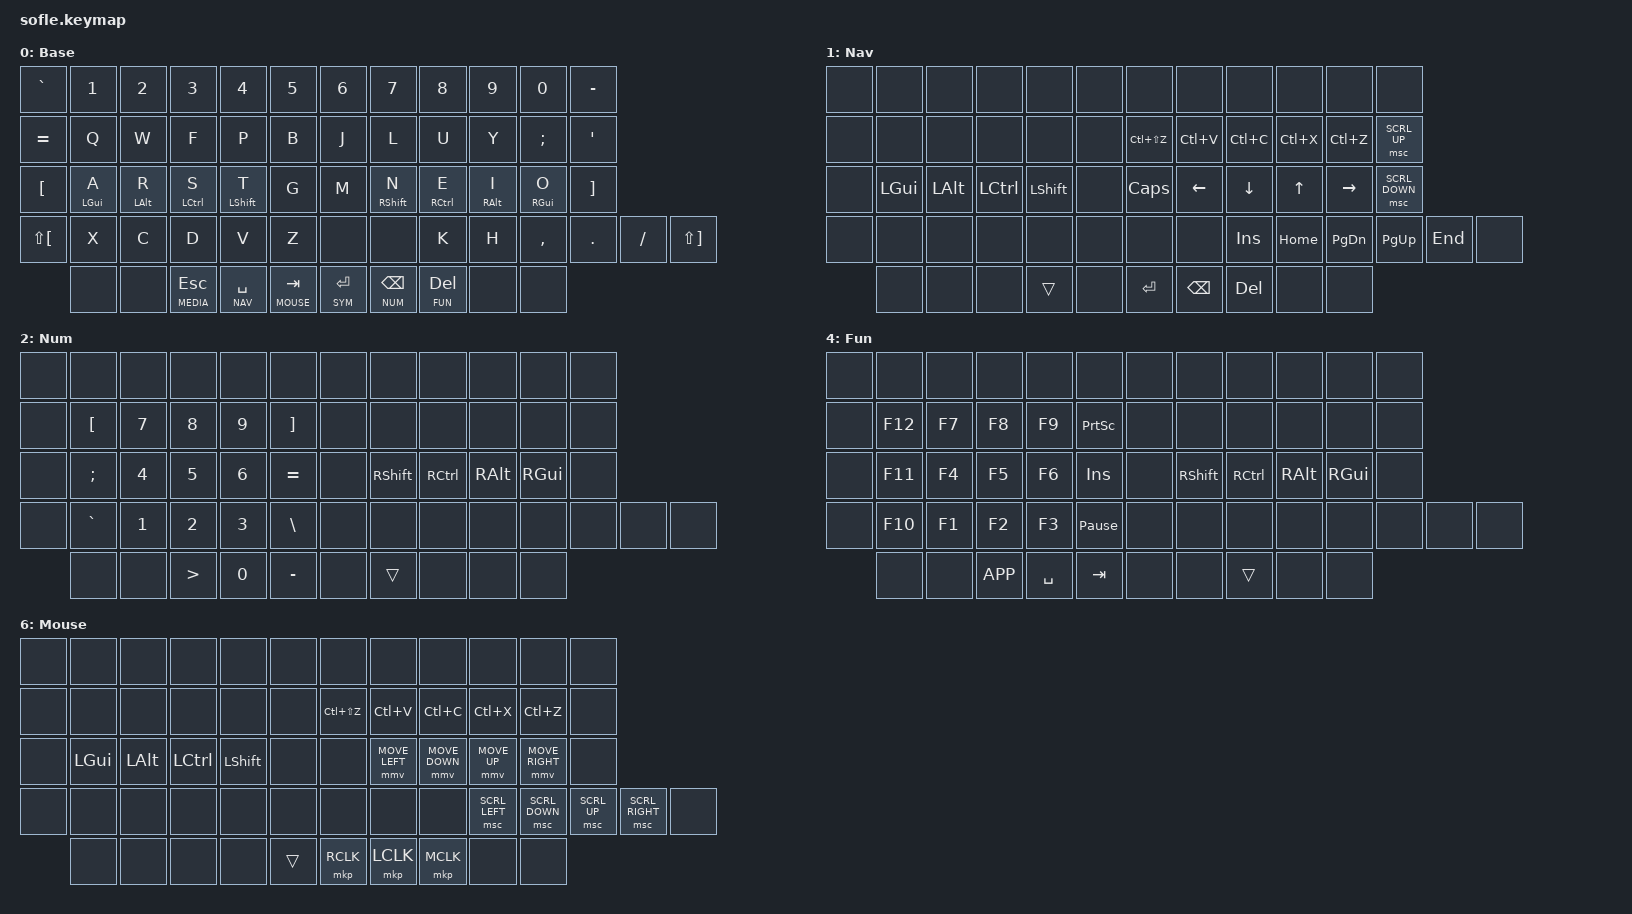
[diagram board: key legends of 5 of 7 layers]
/*
 * SPDX-License-Identifier: MIT
 */

#include <behaviors.dtsi>
#include <dt-bindings/zmk/keys.h>
#include <dt-bindings/zmk/rgb.h>
#include <dt-bindings/zmk/ext_power.h>
#include <dt-bindings/zmk/bt.h>
#include <dt-bindings/zmk/pointing.h>
#include <dt-bindings/zmk/outputs.h>

/* Layers */
#define BASE      0
#define NAV       1
#define NUM       2
#define SYM       3
#define FUN       4
#define MEDIA     5
#define MOUSE     6

/* Miryoku-ish tuning */
#define TAPPING_TERM 280
#define QUICK_TAP    175
#define U_UND &kp LC(Z)
#define U_RDO &kp LC(LS(Z))
#define U_CPY &kp LC(C)
#define U_PST &kp LC(V)
#define U_CUT &kp LC(X)

/ {
  behaviors {
    hm: homerow_mods {
      compatible = "zmk,behavior-hold-tap";
      label = "HM";
      #binding-cells = <2>;
      tapping-term-ms = <TAPPING_TERM>;
      quick-tap-ms = <QUICK_TAP>;
      flavor = "balanced";
      bindings = <&kp>, <&kp>;
    };

    lt: layer_tap {
      compatible = "zmk,behavior-hold-tap";
      label = "LT";
      #binding-cells = <2>;
      tapping-term-ms = <TAPPING_TERM>;
      quick-tap-ms = <QUICK_TAP>;
      flavor = "balanced";
      bindings = <&mo>, <&kp>;
    };

    enc_scroll: enc_scroll {
      compatible = "zmk,behavior-sensor-rotate";
      label = "ENC_SCROLL";
      #sensor-binding-cells = <0>;
      bindings = <&msc SCRL_UP>, <&msc SCRL_DOWN>;
    };

    rgb_toggle_morph: rgb_toggle_morph { 
      compatible = "zmk,behavior-mod-morph";
      #binding-cells = <0>;
      mods = <(MOD_LSFT|MOD_RSFT)>;
      bindings = <&rgb_ug RGB_TOG>, <&rgb_ug RGB_OFF>;
    };

    rgb_eff_morph: rgb_val_morph {
      compatible = "zmk,behavior-mod-morph";
      #binding-cells = <0>;
      mods = <(MOD_LSFT|MOD_RSFT)>;
      bindings = <&rgb_ug RGB_EFF>, <&rgb_ug RGB_EFR>;
    };

    rgb_hue_morph: rgb_hue_morph {
      compatible = "zmk,behavior-mod-morph";
      #binding-cells = <0>;
      mods = <(MOD_LSFT|MOD_RSFT)>;
      bindings = <&rgb_ug RGB_HUI>, <&rgb_ug RGB_HUD>;
    };

    rgb_sat_morph: rgb_sat_morph {
      compatible = "zmk,behavior-mod-morph";
      #binding-cells = <0>;
      mods = <(MOD_LSFT|MOD_RSFT)>;
      bindings = <&rgb_ug RGB_SAI>, <&rgb_ug RGB_SAD>;
    };

    vol_morph: vol_morph {
      compatible = "zmk,behavior-mod-morph";
      #binding-cells = <0>;
      mods = <(MOD_LSFT|MOD_RSFT)>;
      bindings = <&rgb_ug RGB_BRI>, <&rgb_ug RGB_BRD>;
    };
  };

  combos {
    compatible = "zmk,combos";

    combo_dongle_bootloader {
      timeout-ms = <30>;
      key-positions = <50 51 58 59>;
      bindings = <&bootloader>;
    };

    combo_unlock_zmk_studio {
      timeout-ms = <30>;
      key-positions = <50 59>;
      bindings = <&studio_unlock>;
    };
  };

  keymap {
    compatible = "zmk,keymap";

    /* =========================
     * BASE (Colemak-DH Mod-ish)
     * ========================= */
    base_layer {
      display-name = "Base";
      bindings = <
        /* Left */ /* Right */
        &kp GRAVE        &kp N1        &kp N2        &kp N3        &kp N4        &kp N5 &kp N6           &kp N7        &kp N8        &kp N9        &kp N0        &kp MINUS
        &kp EQUAL        &kp Q         &kp W         &kp F         &kp P         &kp B &kp J            &kp L         &kp U         &kp Y         &kp SEMI      &kp QUOT
        &kp LBKT         &hm LGUI A    &hm LALT R    &hm LCTRL S   &hm LSHFT T   &kp G &kp M            &hm RSHFT N   &hm RCTRL E   &hm RALT I    &hm RGUI O    &kp RBKT
        &kp LS(LBKT)     &kp X         &kp C         &kp D         &kp V         &kp Z         &none &none  &kp K   &kp H   &kp COMMA &kp DOT &kp FSLH  &kp LS(RBKT)
        /* Thumbs (center) */ /* Thumbs (right) */ 
                         &none         &none         &lt MEDIA ESC  &lt NAV SPACE  &lt MOUSE TAB &lt SYM ENTER     &lt NUM BSPC   &lt FUN DEL     &none         &none

      >;

      sensor-bindings = <&inc_dec_kp C_VOL_UP C_VOL_DN &enc_scroll>;
    };

    /* =========================
     * NAV (right-hand nav/edit)
     * ========================= */
    nav_layer {
      display-name = "Nav";
      bindings = <
        /* Left */ /* Right */
        &none            &none         &none         &none         &none         &none &none            &none         &none         &none         &none         &none
        &none            &none         &none         &none         &none         &none &kp LC(LS(Z))    U_PST     U_CPY     U_CUT     U_UND     &msc SCRL_UP
        &none            &kp LGUI      &kp LALT      &kp LCTRL     &kp LSHFT     &none &kp CAPS         &kp LEFT      &kp DOWN      &kp UP        &kp RIGHT     &msc SCRL_DOWN
        &none            &none         &none         &none         &none         &none         &none &none            &kp INS       &kp HOME      &kp PG_DN     &kp PG_UP     &kp END       &none

        /* Thumbs */ /* Thumbs (FIX: no &lt here) */ 
                         &none         &none         &none         &trans        &none &kp ENTER        &kp BSPC      &kp DEL       &none         &none


      >;

      sensor-bindings = <&inc_dec_kp C_VOL_UP C_VOL_DN &enc_scroll>;
    };

    /* =========================
     * NUM (left-hand num/sym)
     * ========================= */
    num_layer {
      display-name = "Num";
      bindings = <
        /* Left */ /* Right */
        &none            &none         &none         &none         &none         &none &none            &none         &none         &none         &none         &none
        &none            &kp LBKT      &kp N7        &kp N8        &kp N9        &kp RBKT &none            &none         &none         &none         &none         &none
        &none            &kp SEMI      &kp N4        &kp N5        &kp N6        &kp EQUAL &none            &kp RSHFT     &kp RCTRL     &kp RALT      &kp RGUI      &none 
        &none            &kp GRAVE     &kp N1        &kp N2        &kp N3        &kp BSLH      &none &none            &none         &none         &none         &none         &none         &none

        /* Thumbs */  /* Thumbs */ 
                         &none         &none         &kp GT        &kp N0        &kp MINUS &none            &trans        &none         &none         &none
      >;

      sensor-bindings = <&inc_dec_kp C_VOL_UP C_VOL_DN &enc_scroll>;
    };

    /* =========================
     * SYM (shifted symbols)
     * ========================= */
    sym_layer {
      display-name = "Sym";
      bindings = <
        /* Left */ /* Right */ 
        &none            &none         &none         &none         &none         &none &none            &none         &none         &none         &none         &none
        &none            &kp LS(LBKT)  &kp LS(N7)    &kp LS(N8)    &kp LS(N9)    &kp LS(RBKT) &none            &none         &none         &none         &none         &none
        &none            &kp LS(SEMI)  &kp LS(N4)    &kp LS(N5)    &kp LS(N6)    &kp PLUS &none            &kp RSHFT     &kp RCTRL     &kp RALT      &kp RGUI      &none
        &none            &kp LS(GRAVE) &kp LS(N1)    &kp LS(N2)    &kp LS(N3)    &kp LS(BSLH)  &none &none            &none         &none         &none         &none         &none
        /* Thumbs */    /* Thumbs */ 
                         &none         &none         &kp LBKT      &kp RBKT      &kp LS(MINUS) &none            &trans        &none         &none         &none


      >;

      sensor-bindings = <&inc_dec_kp C_VOL_UP C_VOL_DN &enc_scroll>;
    };

    /* =========================
     * FUN (F-keys + system)
     * ========================= */
    function_layer {
      display-name = "Fun";
      bindings = <
        /* Left */ /* Right */
        &none            &none         &none         &none         &none         &none &none            &none         &none         &none         &none         &none
        &none            &kp F12       &kp F7        &kp F8        &kp F9        &kp PSCRN &none            &none         &none         &none         &none         &none
        &none            &kp F11       &kp F4        &kp F5        &kp F6        &kp INS &none            &kp RSHFT     &kp RCTRL     &kp RALT      &kp RGUI      &none
        &none            &kp F10       &kp F1        &kp F2        &kp F3        &kp PAUSE_BREAK     &none &none            &none         &none         &none         &none         &none         &none

        /* Thumbs */ /* Thumbs */
                         &none         &none         &kp K_APP       &kp SPACE     &kp TAB &none            &none         &trans        &none         &none


      >;

      sensor-bindings = <&inc_dec_kp C_VOL_UP C_VOL_DN &enc_scroll>;
    };

    /* =========================
     * MEDIA (RGB/BT/Output/Power)
     * ========================= */
    media_layer {
      display-name = "Media";
      bindings = <
        /* Left */  /* Right */ 
        &none            &none              &none            &none            &none            &none &none            &none              &none            &none            &none            &none            &none
        &none            &none              &none            &none            &none            &none &none            &rgb_toggle_morph        &none        &rgb_hue_morph    &rgb_sat_morph   &rgb_eff_morph
        &none            &kp LGUI           &kp LALT         &kp LCTRL        &kp LSHFT        &none &none            &ext_power EP_TOG  &kp C_PREV       &kp C_VOL_DN      &kp C_VOL_UP     &kp C_NEXT
        &none            &none              &none            &none            &none            &none            &none &none              &out OUT_TOG     &bt BT_SEL 0      &bt BT_SEL 1     &bt BT_SEL 2     &bt BT_SEL 3 &none
        /* Thumbs */   /* Thumbs */ 
                         &none              &none            &trans           &none            &none &kp C_STOP       &kp C_PP           &kp C_MUTE       &none            &none


      >;

      sensor-bindings = <&inc_dec_kp C_VOL_UP C_VOL_DN &enc_scroll>;
    };

    /* =========================
     * MOUSE (movement + wheel + buttons)
     * ========================= */
    mouse_layer {
      display-name = "Mouse";
      bindings = <
        /* Left */
        &none            &none         &none            &none            &none            &none /* Right */ &none            &none         &none            &none            &none            &none
        &none            &none         &none            &none            &none            &none U_RDO        U_PST     U_CPY        U_CUT        U_UND        &none
        &none            &kp LGUI      &kp LALT         &kp LCTRL        &kp LSHFT        &none &none            &mmv MOVE_LEFT &mmv MOVE_DOWN  &mmv MOVE_UP     &mmv MOVE_RIGHT  &none
        &none            &none         &none            &none            &none            &none            &none &none            &none         &msc SCRL_LEFT   &msc SCRL_DOWN   &msc SCRL_UP     &msc SCRL_RIGHT  &none

        /* Thumbs */
                         &none         &none            &none            &none            &trans

        /* Thumbs */
        &mkp RCLK        &mkp LCLK     &mkp MCLK        &none            &none

      >;

      sensor-bindings = <&inc_dec_kp C_VOL_UP C_VOL_DN &enc_scroll>;
    };

    extra1 { status = "reserved"; };
    extra2 { status = "reserved"; };
    extra3 { status = "reserved"; };
    extra4 { status = "reserved"; };
    extra5 { status = "reserved"; };
    extra6 { status = "reserved"; };
    extra7 { status = "reserved"; };
    extra8 { status = "reserved"; };
  };
};
